# R7FA6M1AD register map
Vendor: Renesas; Series: RA6; File version: 1.2
CPU: CM4 r0p1, little endian, MPU, FPU, VTOR, 4 interrupt priority bits
Registers are 8-bit, read-write, reset 0x0 unless marked. A register's access mark holds for its fields unless they carry their own. Offsets are from the block's base; [hi:lo] are bit positions.

## QSPI — Quad,SPI
Base 0x64000000
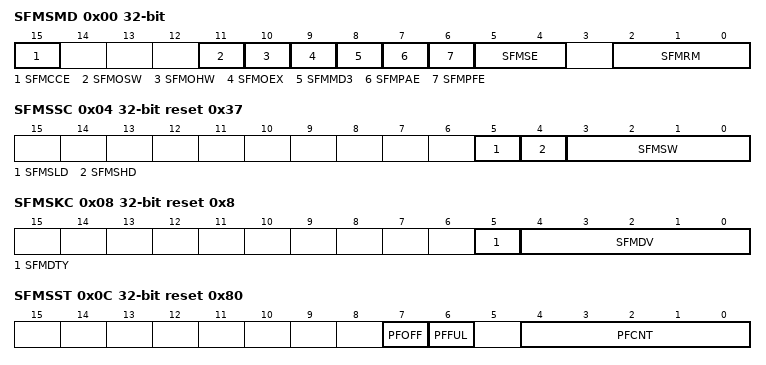
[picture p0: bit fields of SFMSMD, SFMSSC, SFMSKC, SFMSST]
0x00 SFMSMD 32-bit — Transfer Mode Control Register
  [15] SFMCCE — Read instruction code selection.
  [11] SFMOSW — Setup time adjustment for serial transmission
  [10] SFMOHW — Hold time adjustment for serial transmission
  [9] SFMOEX — Extension of the I/O buffer output enable signal for the serial interface
  [8] SFMMD3 — SPI mode selection. An initial value is determined by input to CFGMD3.
  [7] SFMPAE — Selection of the function for stopping prefetch at locations other than on byte boundaries
  [6] SFMPFE — Selection of the prefetch function
  [5:4] SFMSE — Selection of the prefetch function
  [2:0] SFMRM — Serial interface read mode selection
0x04 SFMSSC 32-bit reset 0x37 — Chip Selection Control Register
  [5] SFMSLD — QSSL signal output timing selection
  [4] SFMSHD — QSSL signal release timing selection
  [3:0] SFMSW — Selection of a minimum high,level width of the QSSL signal
0x08 SFMSKC 32-bit reset 0x8 — Clock Control Register
  [5] SFMDTY — Selection of a duty ratio correction function for the SCK signal
  [4:0] SFMDV — Serial interface reference cycle selection (* Pay attention to the irregularity.)NOTE: When PCLKA multiplied by an odd number is selected, the high,level width of the SCK signal is longer than the low,level width by 1 x PCLKA before duty ratio correction.
0x0C SFMSST 32-bit ro reset 0x80 — Status Register
  [7] PFOFF — Prefetch function operation state
  [6] PFFUL — Prefetch buffer state
  [4:0] PFCNT — Number of bytes of prefetched dataRange: 00000 - 10010 (No combination other than the above is available.)
0x10 SFMCOM 32-bit (reset mask 0xFFFFFF00) — Communication Port Register
  [7:0] SFMD — Port for direct communication with the SPI bus.Input/output to and from this port is converted to an SPI bus cycle. This port is accessible in the direct communication mode (DCOM=1) only.Access to this port is ignored in the ROM access mode.
0x14 SFMCMD 32-bit — Communication Mode Control Register
  [0] DCOM — Selection of a mode of communication with the SPI bus
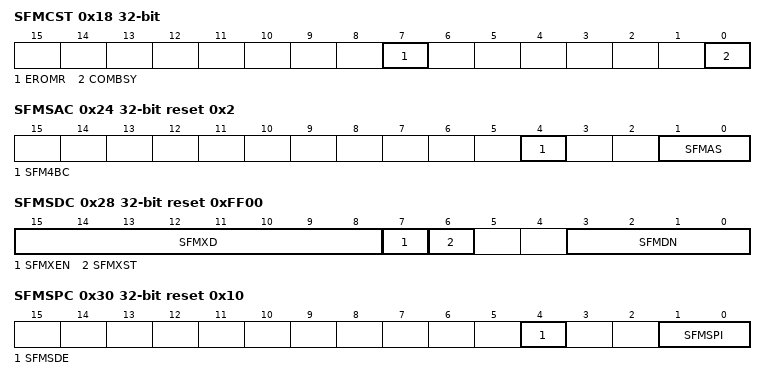
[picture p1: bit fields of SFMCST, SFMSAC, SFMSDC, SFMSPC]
0x18 SFMCST 32-bit — Communication Status Register
  [7] EROMR write-0-clears read-modifies — Status of ROM access detection in the direct communication modeNOTE: Writing of 0 only is possible. Writing of 1 is ignored.
  [0] COMBSY ro — SPI bus cycle completion state in direct communication
0x20 SFMSIC 32-bit — Instruction Code Register
  [7:0] SFMCIC — Serial ROM instruction code to substitute
0x24 SFMSAC 32-bit reset 0x2 — Address Mode Control Register
  [4] SFM4BC — Selection of a default instruction code, when Serial Interface address width is selected 4 bytes.
  [1:0] SFMAS — Selection the number of address bits of the serial interface
0x28 SFMSDC 32-bit reset 0xFF00 — Dummy Cycle Control Register
  [15:8] SFMXD — Mode data for serial ROM. (Control XIP mode)
  [7] SFMXEN — XIP mode permission
  [6] SFMXST ro — XIP mode status
  [3:0] SFMDN — Selection of the number of dummy cycles of Fast Read instructions
0x30 SFMSPC 32-bit reset 0x10 — SPI Protocol Control Register
  [4] SFMSDE — Selection of the minimum time of input output switch, when Dual SPI protocol or Quad SPI protocol is selected.
  [1:0] SFMSPI — Selection of SPI protocolNOTE: Serial ROM's SPI protocol is required to be set by software separately.
0x34 SFMPMD 32-bit — Port Control Register
  [2] SFMWPL — Specify level of WP pin
0x804 SFMCNT1 32-bit — External QSPI Address Register 1
  [31:26] QSPI_EXT — BANK Switching AddressWhen accessing from 0x6000_0000 to 0x63FF_FFFF, Addres bus is Set QSPI_EXT[5:0] to high,order 6bits of SHADDR[31:0]NOTE: Setting 6'h3F is prihibited.
